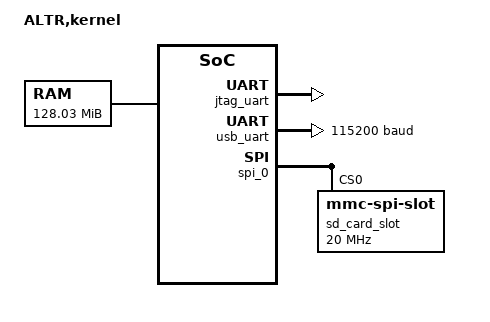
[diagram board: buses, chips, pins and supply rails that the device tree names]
/*
 * This devicetree is generated by sopc2dts on Sun Apr 20 14:36:03 PDT 2014
 * Sopc2dts is written by Walter Goossens <waltergoossens@home.nl>
 * in cooperation with the nios2 community <Nios2-dev@sopc.et.ntust.edu.tw>
 */
/dts-v1/;

/ {
	model = "ALTR,kernel";
	compatible = "ALTR,kernel";
	#address-cells = < 1 >;
	#size-cells = < 1 >;

	cpus {
		#address-cells = < 1 >;
		#size-cells = < 0 >;

		cpu: cpu@0x0 {
			device_type = "cpu";
			compatible = "ALTR,nios2-13.1", "ALTR,nios2-1.0", "altr,nios2-1.0";
			reg = < 0x00000000 >;
			interrupt-controller;
			#interrupt-cells = < 1 >;
			clock-frequency = < 100000000 >;	/* embeddedsw.dts.params.clock-frequency type NUMBER */
			dcache-line-size = < 32 >;	/* embeddedsw.dts.params.dcache-line-size type NUMBER */
			icache-line-size = < 32 >;	/* embeddedsw.dts.params.icache-line-size type NUMBER */
			dcache-size = < 32768 >;	/* embeddedsw.dts.params.dcache-size type NUMBER */
			icache-size = < 32768 >;	/* embeddedsw.dts.params.icache-size type NUMBER */
			ALTR,implementation = "fast";	/* embeddedsw.dts.params.ALTR,implementation type STRING */
			ALTR,pid-num-bits = < 8 >;	/* embeddedsw.dts.params.ALTR,pid-num-bits type NUMBER */
			ALTR,tlb-num-ways = < 16 >;	/* embeddedsw.dts.params.ALTR,tlb-num-ways type NUMBER */
			ALTR,tlb-num-entries = < 128 >;	/* embeddedsw.dts.params.ALTR,tlb-num-entries type NUMBER */
			ALTR,tlb-ptr-sz = < 7 >;	/* embeddedsw.dts.params.ALTR,tlb-ptr-sz type NUMBER */
			ALTR,has-div = < 1 >;	/* embeddedsw.dts.params.ALTR,has-div type NUMBER */
			ALTR,has-mul = < 1 >;	/* embeddedsw.dts.params.ALTR,has-mul type NUMBER */
			ALTR,reset-addr = < 3221225472 >;	/* embeddedsw.dts.params.ALTR,reset-addr type NUMBER */
			ALTR,fast-tlb-miss-addr = < 3221487616 >;	/* embeddedsw.dts.params.ALTR,fast-tlb-miss-addr type NUMBER */
			ALTR,exception-addr = < 3489660960 >;	/* embeddedsw.dts.params.ALTR,exception-addr type NUMBER */
			ALTR,has-initda = < 1 >;	/* embeddedsw.dts.params.ALTR,has-initda type NUMBER */
		}; //end cpu@0x0 (cpu)
	}; //end cpus

	memory@0 {
		device_type = "memory";
		reg = < 0x10000000 0x08000000 
			0x00020000 0x00008000 
			0x00040000 0x00000400 >;
	}; //end memory@0

	sopc0: sopc@0 {
		device_type = "soc";
		ranges;
		#address-cells = < 1 >;
		#size-cells = < 1 >;
		compatible = "ALTR,avalon", "simple-bus";
		bus-frequency = < 100000000 >;

		jtag_uart: serial@0x3000 {
			compatible = "ALTR,juart-13.1", "ALTR,juart-1.0", "altr,juart-1.0";
			reg = < 0x00003000 0x00000008 >;
			interrupt-parent = < &cpu >;
			interrupts = < 0 >;
		}; //end serial@0x3000 (jtag_uart)

		led: gpio@0x4000 {
			compatible = "ALTR,pio-13.1", "ALTR,pio-1.0", "altr,pio-1.0";
			reg = < 0x00004000 0x00000010 >;
			width = < 4 >;	/* embeddedsw.dts.params.width type NUMBER */
			resetvalue = < 0 >;	/* embeddedsw.dts.params.resetvalue type NUMBER */
			#gpio-cells = < 2 >;
			gpio-controller;
		}; //end gpio@0x4000 (led)

		timer_0: timer@0x6040 {
			compatible = "ALTR,timer-13.1", "ALTR,timer-1.0", "altr,timer-1.0";
			reg = < 0x00006040 0x00000020 >;
			interrupt-parent = < &cpu >;
			interrupts = < 2 >;
			clock-frequency = < 40000000 >;	/* embeddedsw.dts.params.clock-frequency type NUMBER */
		}; //end timer@0x6040 (timer_0)

		usb_uart: serial@0x7800 {
			compatible = "ALTR,uart-13.1", "ALTR,uart-1.0", "altr,uart-1.0";
			reg = < 0x00007800 0x00000020 >;
			interrupt-parent = < &cpu >;
			interrupts = < 4 >;
			current-speed = < 115200 >;	/* embeddedsw.dts.params.current-speed type NUMBER */
			clock-frequency = < 40000000 >;	/* embeddedsw.dts.params.clock-frequency type NUMBER */
		}; //end serial@0x7800 (usb_uart)

		sysid: sysid@0x1800 {
			compatible = "ALTR,sysid-13.1", "ALTR,sysid-1.0", "altr,sysid-1.0";
			reg = < 0x00001800 0x00000008 >;
			id = < 1577 >;	/* embeddedsw.dts.params.id type NUMBER */
			timestamp = < 1398028939 >;	/* embeddedsw.dts.params.timestamp type NUMBER */
		}; //end sysid@0x1800 (sysid)

		epcs: spi@0x400 {
			compatible = "ALTR,spi-13.1", "ALTR,spi-1.0";
			reg = < 0x00000400 0x00000400 >;
			interrupt-parent = < &cpu >;
			interrupts = < 1 >;
			bank-width = < 2 >;
			device-width = < 1 >;
			#address-cells = < 1 >;
			#size-cells = < 0 >;
			status = "disabled";	/* appended from boardinfo */

			m25p80@0 {
				compatible = "m25p80";
				spi-max-frequency = < 25000000 >;
				reg = < 0 >;
			}; //end m25p80@0
		}; //end spi@0x400 (epcs)

		spi_0: spi@0x6060 {
			compatible = "ALTR,spi-13.1", "ALTR,spi-1.0", "altr,spi-1.0";
			reg = < 0x00006060 0x00000020 >;
			interrupt-parent = < &cpu >;
			interrupts = < 3 >;
			#address-cells = < 1 >;	/* appended from boardinfo */
			#size-cells = < 0 >;	/* appended from boardinfo */

			sd_card_slot: mmc-slot@0 {
				compatible = "mmc-spi-slot";	/* appended from boardinfo */
				reg = < 0x00000000 >;	/* appended from boardinfo */
				voltage-ranges = < 3300 3300 >;	/* appended from boardinfo */
				spi-max-frequency = < 20000000 >;	/* appended from boardinfo */
			}; //end mmc-slot@0 (sd_card_slot)
		}; //end spi@0x6060 (spi_0)
	}; //end sopc@0 (sopc0)

	chosen {
		bootargs = "debug console=ttyAL0,115200 root=/dev/mmcblk0p2 rootwait";
	}; //end chosen
}; //end /
